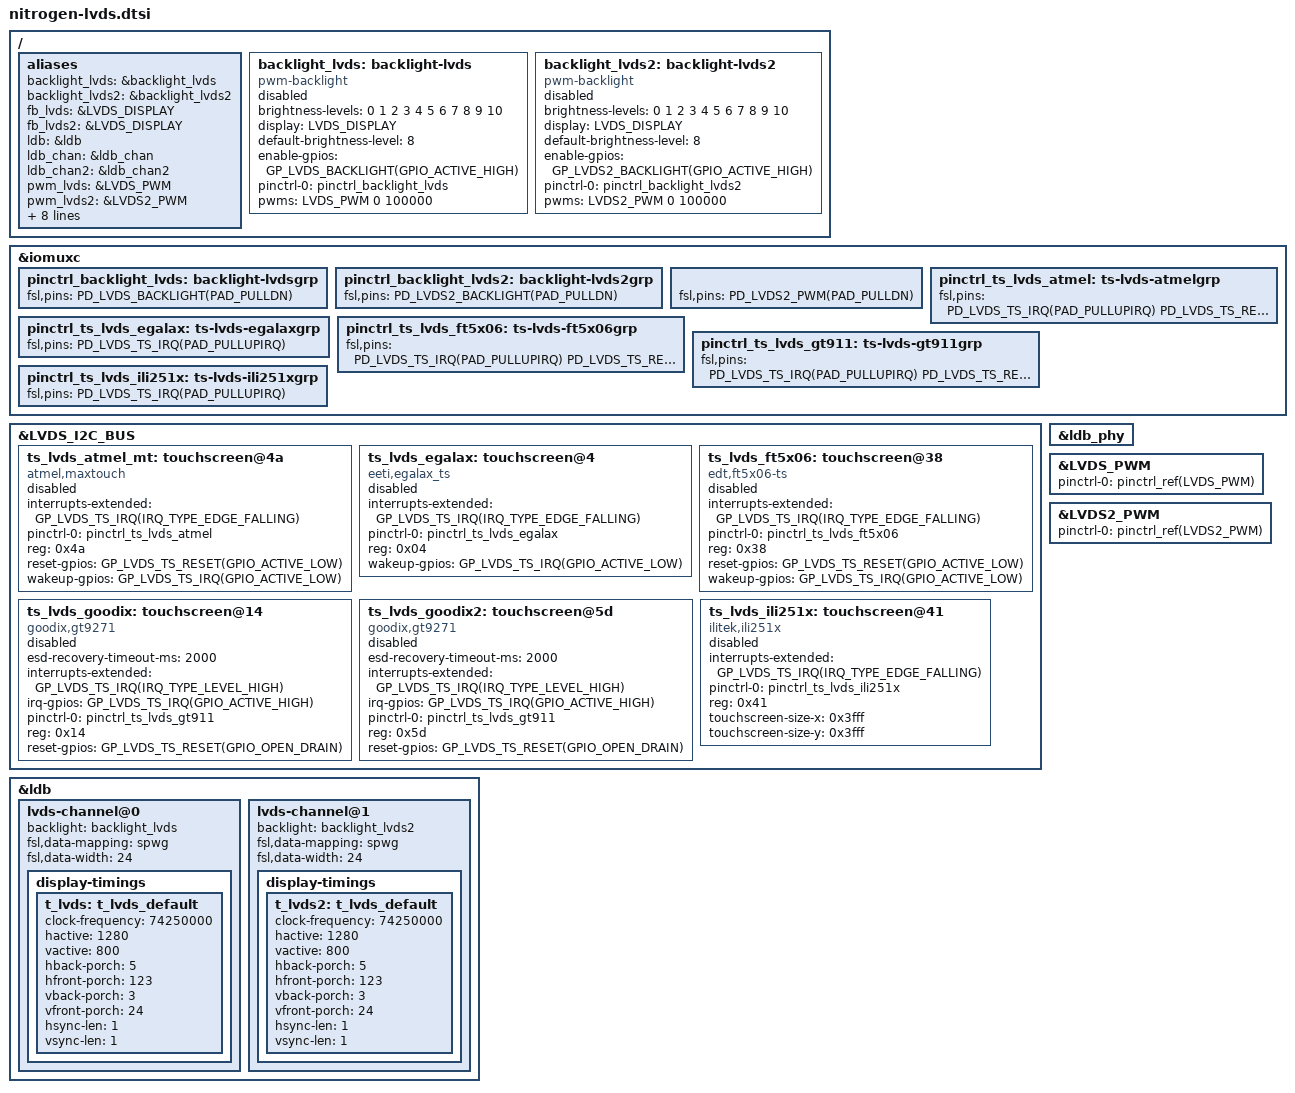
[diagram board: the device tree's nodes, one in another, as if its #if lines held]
// SPDX-License-Identifier: (GPL-2.0+ OR MIT)
/*
 * Copyright 2023 Boundary Devices
 */
#define concat(a, b)   _concat_(a, b)
#define _concat_(a, b)  a ## b
#define pinctrl(a) concat(pinctrl_, a): concat(a, grp)
#define pinctrl_ref(a) <&concat(pinctrl_, a)>

&iomuxc {
	pinctrl_backlight_lvds: backlight-lvdsgrp {
		fsl,pins = <
			PD_LVDS_BACKLIGHT(PAD_PULLDN)
		>;
	};

#ifdef LVDS2_BACKLIGHT_PAD
	pinctrl_backlight_lvds2: backlight-lvds2grp {
		fsl,pins = <
			PD_LVDS2_BACKLIGHT(PAD_PULLDN)
		>;
	};
#endif

#define VAL_pwm1	1
#define VAL_pwm2	2
#define VAL_pwm3	3
#define VAL_pwm4	4
#define VAL(a) concat(VAL_, a)

	pinctrl(LVDS_PWM) {
		fsl,pins = <
			PD_LVDS_PWM(PAD_PULLDN)
		>;
	};

#if VAL(LVDS2_PWM) != VAL(LVDS_PWM)
	pinctrl(LVDS2_PWM) {
		fsl,pins = <
			PD_LVDS2_PWM(PAD_PULLDN)
		>;
	};
#endif

	pinctrl_ts_lvds_atmel: ts-lvds-atmelgrp {
		fsl,pins = <
			PD_LVDS_TS_IRQ(PAD_PULLUPIRQ)
			PD_LVDS_TS_RESET(PAD_PULLDN)
		>;
	};

	pinctrl_ts_lvds_egalax: ts-lvds-egalaxgrp {
		fsl,pins = <
			PD_LVDS_TS_IRQ(PAD_PULLUPIRQ)
		>;
	};

	pinctrl_ts_lvds_ft5x06: ts-lvds-ft5x06grp {
		fsl,pins = <
			PD_LVDS_TS_IRQ(PAD_PULLUPIRQ)
			PD_LVDS_TS_RESET(PAD_PULLDN)
		>;
	};

	pinctrl_ts_lvds_gt911: ts-lvds-gt911grp {
		fsl,pins = <
			PD_LVDS_TS_IRQ(PAD_PULLUPIRQ)
			PD_LVDS_TS_RESET(PAD_PULLUP)
		>;
	};

	pinctrl_ts_lvds_ili251x: ts-lvds-ili251xgrp {
		fsl,pins = <
			PD_LVDS_TS_IRQ(PAD_PULLUPIRQ)
		>;
	};
};

/ {
	aliases {
		backlight_lvds = &backlight_lvds;
#if (VAL(LVDS2_PWM) != VAL(LVDS_PWM)) || defined(LVDS2_BACKLIGHT_PAD)
		backlight_lvds2 = &backlight_lvds2;
#endif
		fb_lvds = &LVDS_DISPLAY;
		fb_lvds2 = &LVDS_DISPLAY;
		ldb = &ldb;
		ldb_chan = &ldb_chan;
		ldb_chan2 = &ldb_chan2;
		pwm_lvds = &LVDS_PWM;
		pwm_lvds2 = &LVDS2_PWM;
		t_lvds = &t_lvds;
		t_lvds2 = &t_lvds2;
		ts_lvds_atmel_mt = &ts_lvds_atmel_mt;
		ts_lvds_egalax = &ts_lvds_egalax;
		ts_lvds_ft5x06 = &ts_lvds_ft5x06;
		ts_lvds_goodix = &ts_lvds_goodix;
#ifdef LVDS_NO_TS_RESET
		ts_lvds_goodix2 = &ts_lvds_goodix2;
#endif
		ts_lvds_ili251x = &ts_lvds_ili251x;
	};

	backlight_lvds: backlight-lvds {
		brightness-levels = <0 1 2 3 4 5 6 7 8 9 10>;
		compatible = "pwm-backlight";
		display = <&LVDS_DISPLAY>;
		default-brightness-level = <8>;
		enable-gpios = GP_LVDS_BACKLIGHT(GPIO_ACTIVE_HIGH);
		pinctrl-names = "default";
		pinctrl-0 = <&pinctrl_backlight_lvds>;
		pwms = <&LVDS_PWM 0 100000>;
		status = "disabled";
	};

#if (VAL(LVDS2_PWM) != VAL(LVDS_PWM)) || defined(LVDS2_BACKLIGHT_PAD)
	backlight_lvds2: backlight-lvds2 {
		brightness-levels = <0 1 2 3 4 5 6 7 8 9 10>;
		compatible = "pwm-backlight";
		display = <&LVDS_DISPLAY>;
		default-brightness-level = <8>;
#ifdef LVDS2_BACKLIGHT_PAD
		enable-gpios = GP_LVDS2_BACKLIGHT(GPIO_ACTIVE_HIGH);
		pinctrl-names = "default";
		pinctrl-0 = <&pinctrl_backlight_lvds2>;
#endif
		pwms = <&LVDS2_PWM 0 100000>;
		status = "disabled";
	};
#endif

};

&LVDS_I2C_BUS {
	ts_lvds_atmel_mt: touchscreen@4a {
		compatible = "atmel,maxtouch";
		interrupts-extended = GP_LVDS_TS_IRQ(IRQ_TYPE_EDGE_FALLING);
		pinctrl-names = "default";
		pinctrl-0 = <&pinctrl_ts_lvds_atmel>;
		reg = <0x4a>;
		reset-gpios = GP_LVDS_TS_RESET(GPIO_ACTIVE_LOW);
		wakeup-gpios = GP_LVDS_TS_IRQ(GPIO_ACTIVE_LOW);
		status = "disabled";
	};

	ts_lvds_egalax: touchscreen@4 {
		compatible = "eeti,egalax_ts";
		interrupts-extended = GP_LVDS_TS_IRQ(IRQ_TYPE_EDGE_FALLING);
		pinctrl-names = "default";
		pinctrl-0 = <&pinctrl_ts_lvds_egalax>;
		reg = <0x04>;
		status = "disabled";
		wakeup-gpios = GP_LVDS_TS_IRQ(GPIO_ACTIVE_LOW);
	};

	ts_lvds_ft5x06: touchscreen@38 {
		compatible = "edt,ft5x06-ts";
		interrupts-extended = GP_LVDS_TS_IRQ(IRQ_TYPE_EDGE_FALLING);
		pinctrl-names = "default";
		pinctrl-0 = <&pinctrl_ts_lvds_ft5x06>;
		reg = <0x38>;
#ifndef LVDS_NO_TS_RESET
		reset-gpios = GP_LVDS_TS_RESET(GPIO_ACTIVE_LOW);
#endif
		status = "disabled";
		wakeup-gpios = GP_LVDS_TS_IRQ(GPIO_ACTIVE_LOW);
	};

	ts_lvds_goodix: touchscreen@14 {
		compatible = "goodix,gt9271";
		esd-recovery-timeout-ms = <2000>;
		interrupts-extended = GP_LVDS_TS_IRQ(IRQ_TYPE_LEVEL_HIGH);
		irq-gpios = GP_LVDS_TS_IRQ(GPIO_ACTIVE_HIGH);
		pinctrl-names = "default";
		pinctrl-0 = <&pinctrl_ts_lvds_gt911>;
		reg = <0x14>;
		reset-gpios = GP_LVDS_TS_RESET(GPIO_OPEN_DRAIN);
		status = "disabled";
	};

#ifdef LVDS_NO_TS_RESET
	ts_lvds_goodix2: touchscreen@5d {
		compatible = "goodix,gt9271";
		esd-recovery-timeout-ms = <2000>;
		interrupts-extended = GP_LVDS_TS_IRQ(IRQ_TYPE_LEVEL_HIGH);
		irq-gpios = GP_LVDS_TS_IRQ(GPIO_ACTIVE_HIGH);
		pinctrl-names = "default";
		pinctrl-0 = <&pinctrl_ts_lvds_gt911>;
		reg = <0x5d>;
		reset-gpios = GP_LVDS_TS_RESET(GPIO_OPEN_DRAIN);
		status = "disabled";
	};
#endif

	ts_lvds_ili251x: touchscreen@41 {
		compatible = "ilitek,ili251x";
		interrupts-extended = GP_LVDS_TS_IRQ(IRQ_TYPE_EDGE_FALLING);
		pinctrl-names = "default";
		pinctrl-0 = <&pinctrl_ts_lvds_ili251x>;
		reg = <0x41>;
		status = "disabled";
		touchscreen-size-x = <0x3fff>;
		touchscreen-size-y = <0x3fff>;
	};
};

&ldb {
	lvds-channel@0 {
		backlight = <&backlight_lvds>;
		fsl,data-mapping = "spwg";
		fsl,data-width = <24>;

		display-timings {
			t_lvds: t_lvds_default {
				/* m101nwwb by default */
				clock-frequency = <74250000>;
				hactive = <1280>;
				vactive = <800>;
				hback-porch = <5>;
				hfront-porch = <123>;
				vback-porch = <3>;
				vfront-porch = <24>;
				hsync-len = <1>;
				vsync-len = <1>;
			};
		};
	};

	lvds-channel@1 {
#ifdef LVDS2_BACKLIGHT_PAD
		backlight = <&backlight_lvds2>;
#endif
		fsl,data-mapping = "spwg";
		fsl,data-width = <24>;

		display-timings {
			t_lvds2: t_lvds_default {
				/* m101nwwb by default */
				clock-frequency = <74250000>;
				hactive = <1280>;
				vactive = <800>;
				hback-porch = <5>;
				hfront-porch = <123>;
				vback-porch = <3>;
				vfront-porch = <24>;
				hsync-len = <1>;
				vsync-len = <1>;
			};
		};
	};
};

&ldb_phy {
	status = "okay";
};

&LVDS_PWM {
	pinctrl-names = "default";
	pinctrl-0 = pinctrl_ref(LVDS_PWM);
	status = "okay";
};

#if VAL(LVDS2_PWM) != VAL(LVDS_PWM)
&LVDS2_PWM {
	pinctrl-names = "default";
	pinctrl-0 = pinctrl_ref(LVDS2_PWM);
	status = "okay";
};
#endif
